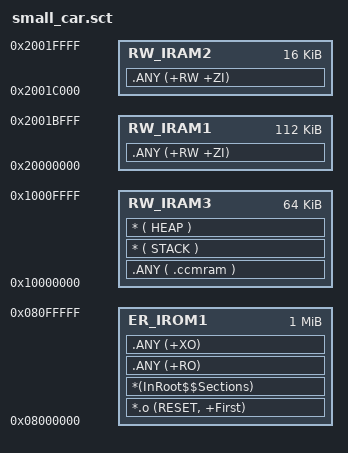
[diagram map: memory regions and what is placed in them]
; *************************************************************
; *** Scatter-Loading Description File generated by uVision ***
; *************************************************************

LR_IROM1 0x08000000 0x00100000  {    ; load region size_region
  ER_IROM1 0x08000000 0x00100000  {  ; load address = execution address
   *.o (RESET, +First)
   *(InRoot$$Sections)
   .ANY (+RO)
   .ANY (+XO)
  }
  RW_IRAM1 0x20000000 0x0001C000  {  ; RW data
   .ANY (+RW +ZI)
  }
  RW_IRAM2 0x2001C000 0x00004000  {
   .ANY (+RW +ZI)
  }

  RW_IRAM3 0x10000000 0x00010000  {  ; CCM 64KB，只有 CPU 能访问
   .ANY ( .ccmram )
   * ( STACK )        ; ★ 栈也放 CCM：不受 DMA 抢总线
   * ( HEAP )
  }
}
